# HK32L0xx register map
Vendor: HKMicroChip Ltd.; Series: HK32L0xx; File version: 1.3
CPU: CM0 r0p0, little endian, no MPU, no FPU, 3 interrupt priority bits
Registers are 32-bit, read-write, reset 0x0 unless marked. A register's access mark holds for its fields unless they carry their own. Offsets are from the block's base; [hi:lo] are bit positions.

## LPUART
Base 0x40004000
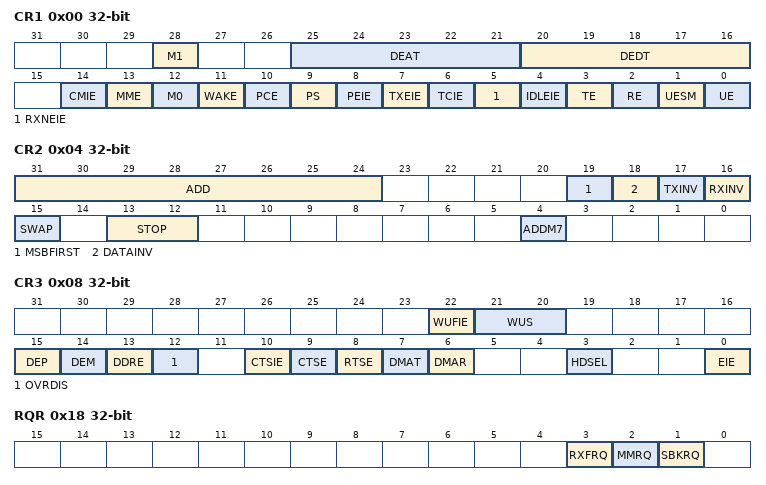
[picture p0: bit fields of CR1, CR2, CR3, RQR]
0x00 CR1
  [28] M1 — Word length
  [25:21] DEAT — Driver Enable assertion time
  [20:16] DEDT — Driver Enable de-assertion time
  [14] CMIE — Character match interrupt enable
  [13] MME — Mute mode enable
  [12] M0 — Word length
  [11] WAKE — Receiver wakeup method
  [10] PCE — Parity control enable
  [9] PS — Parity selection
  [8] PEIE — PE interrupt enable
  [7] TXEIE — interrupt enable
  [6] TCIE — Transfer complete interrupt enable
  [5] RXNEIE — RXNE interrupt enable
  [4] IDLEIE — IDLE interrupt enable
  [3] TE — Transmitter enable
  [2] RE — Receiver enable
  [1] UESM — LPUART enable in Stop mode
  [0] UE — LPUART enable
0x04 CR2
  [31:24] ADD
  [19] MSBFIRST — Most significant bit first
  [18] DATAINV — Binary data inversion
  [17] TXINV — TX pin active level inversion
  [16] RXINV — RX pin active level inversion
  [15] SWAP — Swap TX/RX pins
  [13:12] STOP — STOP bits
  [4] ADDM7 — 7-bit Address Detection/4-bit Address Detection
0x08 CR3
  [22] WUFIE — Wakeup from Stop mode interrupt enable
  [21:20] WUS — Wakeup from Stop mode interrupt flag selection
  [15] DEP — Driver enable polarity selection
  [14] DEM — Driver enable mode
  [13] DDRE — DMA Disable on Reception Error
  [12] OVRDIS — Overrun Disable
  [10] CTSIE — CTS interrupt enable
  [9] CTSE — CTS enable
  [8] RTSE — RTS enable
  [7] DMAT — DMA enable transmitter
  [6] DMAR — DMA enable receiver
  [3] HDSEL — Half-duplex selection
  [0] EIE — Error interrupt enable
0x0C BRR
  [19:0] BRR — Baud Rate Register parameter
0x18 RQR wo
  [3] RXFRQ — Receive data flush request
  [2] MMRQ — Mute mode request
  [1] SBKRQ — Send break request
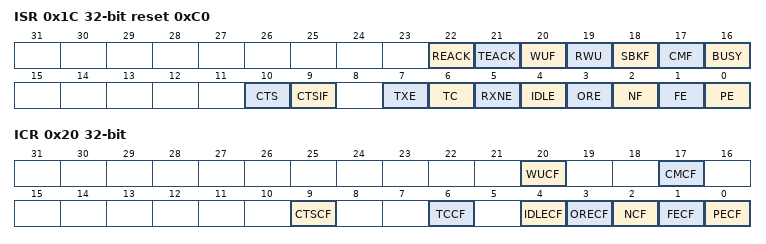
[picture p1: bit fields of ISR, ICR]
0x1C ISR ro reset 0xC0
  [22] REACK — Receive enable acknowledge flag
  [21] TEACK — Transmit enable acknowledge flag
  [20] WUF — Wakeup from Stop mode flag
  [19] RWU — Receiver wakeup from Mute mode
  [18] SBKF — Send break flag
  [17] CMF — Character match flag
  [16] BUSY — Busy flag
  [10] CTS — CTS flag
  [9] CTSIF — CTS interrupt flag
  [7] TXE — Transmit data register empty
  [6] TC — Transmission complete
  [5] RXNE — Read data register not empty
  [4] IDLE — IDLE line detected
  [3] ORE — Overrun error
  [2] NF — START bit Noise detection flag
  [1] FE — Framing error
  [0] PE — Parity error
0x20 ICR wo
  [20] WUCF — Wakeup from Stop mode clear flag
  [17] CMCF — Character match clear flag
  [9] CTSCF — CTS clear flag
  [6] TCCF — Transmission complete clear flag
  [4] IDLECF — Idle line detected clear flag
  [3] ORECF — Overrun error clear flag
  [2] NCF — Noise detected clear flag
  [1] FECF — Framing error clear flag
  [0] PECF — Parity error clear flag
0x24 RDR ro
  [8:0] RDR — Receive data value
0x28 TDR
  [8:0] TDR — Transmit data value

## SPI1
Base 0x40013000
Same registers: SPI2 0x40003800
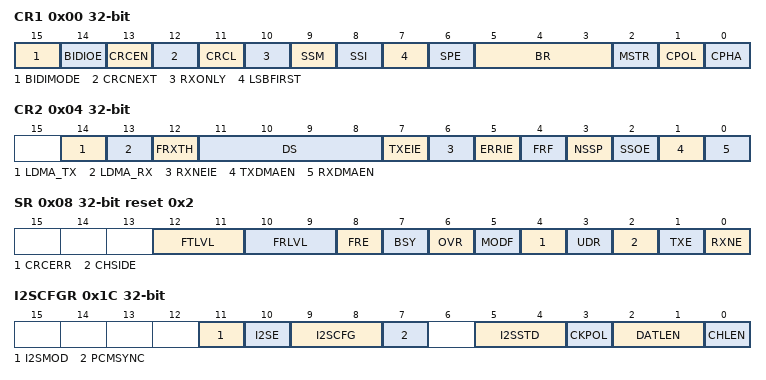
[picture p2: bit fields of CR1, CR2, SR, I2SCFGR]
0x00 CR1
  [15] BIDIMODE — Bidirectional data mode enable
  [14] BIDIOE — Output enable in bidirectional mode
  [13] CRCEN — Hardware CRC calculation enable
  [12] CRCNEXT — Transmit CRC next
  [11] CRCL — CRC length
  [10] RXONLY — Receive only mode enabled
  [9] SSM — Software slave management
  [8] SSI — Internal slave select
  [7] LSBFIRST — Frame format
  [6] SPE — SPI enable
  [5:3] BR — Baud rate control
  [2] MSTR — Master selection
  [1] CPOL — Clock polarity
  [0] CPHA — Clock phase
0x04 CR2
  [14] LDMA_TX — Last DMA transfer for transmission
  [13] LDMA_RX — Last DMA transfer for reception
  [12] FRXTH — FIFO reception threshold
  [11:8] DS — Data size
  [7] TXEIE — Tx buffer empty interrupt enable
  [6] RXNEIE — RX buffer not empty interrupt enable
  [5] ERRIE — Error interrupt enable
  [4] FRF — Frame format
  [3] NSSP — NSS pulse management
  [2] SSOE — SS output enable
  [1] TXDMAEN — Tx buffer DMA enable
  [0] RXDMAEN — Rx buffer DMA enable
0x08 SR access per field reset 0x2
  [12:11] FTLVL ro — FIFO Transmission Level
  [10:9] FRLVL ro — FIFO reception level
  [8] FRE ro — Frame format error
  [7] BSY ro — Busy flag
  [6] OVR ro — Overrun flag
  [5] MODF ro — Mode fault
  [4] CRCERR rw — CRC error flag
  [3] UDR ro — Underrun flag
  [2] CHSIDE ro — Channel side
  [1] TXE ro — Transmit buffer empty
  [0] RXNE ro — Receive buffer not empty
0x0C DR
  [15:0] DR — Data register
0x10 CRCPR reset 0x7
  [15:0] CRCPOLY — CRC polynomial register
0x14 RXCRCR ro
  [15:0] RXCRC
0x18 TXCRCR ro
  [15:0] TXCRC
0x1C I2SCFGR
  [11] I2SMOD — I2S mode selection
  [10] I2SE — I2S enable
  [9:8] I2SCFG — I2S configuration mode
  [7] PCMSYNC — PCM frame synchronization
  [5:4] I2SSTD — I2S standard selection
  [3] CKPOL — Inactive state clock polarity
  [2:1] DATLEN — Data length to be transferred
  [0] CHLEN — Channel length (number of bits per audio channel)
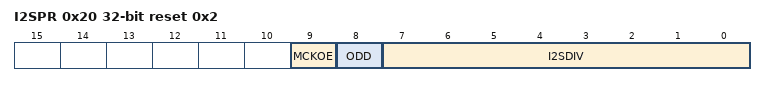
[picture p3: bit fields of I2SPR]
0x20 I2SPR reset 0x2
  [9] MCKOE — Master clock output enable
  [8] ODD — Odd factor for the prescaler
  [7:0] I2SDIV — I2S linear prescaler
0x28 PLUS
  [1] SWAPNS — Swap NSS and SCLK
